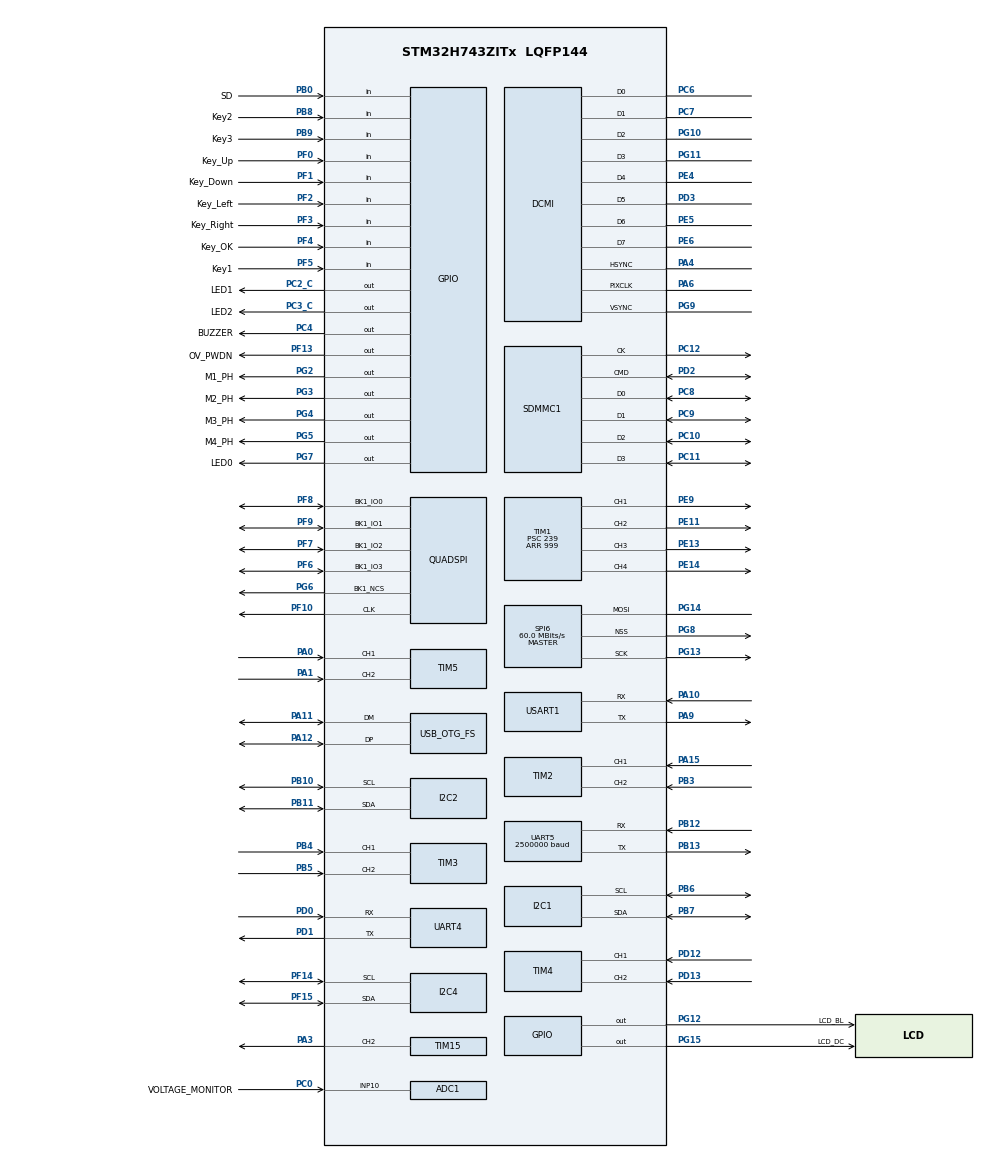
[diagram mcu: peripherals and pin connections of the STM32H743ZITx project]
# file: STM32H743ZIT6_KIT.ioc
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ADC1.Channel-2\#ChannelRegularConversion=ADC_CHANNEL_10
ADC1.NbrOfConversionFlag=1
ADC1.OffsetNumber-2\#ChannelRegularConversion=ADC_OFFSET_NONE
ADC1.OffsetSignedSaturation-2\#ChannelRegularConversion=DISABLE
ADC1.Rank-2\#ChannelRegularConversion=1
ADC1.SamplingTime-2\#ChannelRegularConversion=ADC_SAMPLETIME_387CYCLES_5
ADC1.master=1
Bdma.Request0=SPI6_TX
Bdma.RequestsNb=1
Bdma.SPI6_TX.0.Direction=DMA_MEMORY_TO_PERIPH
Bdma.SPI6_TX.0.EventEnable=DISABLE
Bdma.SPI6_TX.0.Instance=BDMA_Channel0
Bdma.SPI6_TX.0.MemDataAlignment=DMA_MDATAALIGN_HALFWORD
Bdma.SPI6_TX.0.MemInc=DMA_MINC_ENABLE
Bdma.SPI6_TX.0.Mode=DMA_NORMAL
Bdma.SPI6_TX.0.PeriphDataAlignment=DMA_PDATAALIGN_HALFWORD
Bdma.SPI6_TX.0.PeriphInc=DMA_PINC_DISABLE
Bdma.SPI6_TX.0.Polarity=HAL_DMAMUX_REQ_GEN_RISING
Bdma.SPI6_TX.0.Priority=DMA_PRIORITY_HIGH
Bdma.SPI6_TX.0.RequestNumber=1
Bdma.SPI6_TX.0.SignalID=NONE
Bdma.SPI6_TX.0.SyncEnable=DISABLE
Bdma.SPI6_TX.0.SyncPolarity=HAL_DMAMUX_SYNC_NO_EVENT
Bdma.SPI6_TX.0.SyncRequestNumber=1
Bdma.SPI6_TX.0.SyncSignalID=NONE
CORTEX_M7.default_mode_Activation=1
DAC1.DAC_Channel-DAC_OUT1_Int=DAC_CHANNEL_1
DCMI.JPEGMode=DCMI_JPEG_ENABLE
DCMI.PCKPolarity=DCMI_PCKPOLARITY_RISING
DCMI.VSPolarity=DCMI_VSPOLARITY_HIGH
DMA2D.ChromaSubSamplingForeground=DMA2D_CSS_420
DMA2D.ColorMode=DMA2D_OUTPUT_RGB565
DMA2D.InputColorModeForeground=DMA2D_INPUT_YCBCR
DMA2D.Mode=DMA2D_M2M_PFC
Dma.DCMI.1.Direction=DMA_PERIPH_TO_MEMORY
Dma.DCMI.1.EventEnable=DISABLE
Dma.DCMI.1.FIFOMode=DMA_FIFOMODE_ENABLE
Dma.DCMI.1.FIFOThreshold=DMA_FIFO_THRESHOLD_FULL
Dma.DCMI.1.Instance=DMA1_Stream1
Dma.DCMI.1.MemBurst=DMA_MBURST_SINGLE
Dma.DCMI.1.MemDataAlignment=DMA_MDATAALIGN_WORD
Dma.DCMI.1.MemInc=DMA_MINC_ENABLE
Dma.DCMI.1.Mode=DMA_NORMAL
Dma.DCMI.1.PeriphBurst=DMA_PBURST_SINGLE
Dma.DCMI.1.PeriphDataAlignment=DMA_PDATAALIGN_WORD
Dma.DCMI.1.PeriphInc=DMA_PINC_DISABLE
Dma.DCMI.1.Polarity=HAL_DMAMUX_REQ_GEN_RISING
Dma.DCMI.1.Priority=DMA_PRIORITY_VERY_HIGH
Dma.DCMI.1.RequestNumber=1
Dma.DCMI.1.SignalID=NONE
Dma.DCMI.1.SyncEnable=DISABLE
Dma.DCMI.1.SyncPolarity=HAL_DMAMUX_SYNC_NO_EVENT
Dma.DCMI.1.SyncRequestNumber=1
Dma.DCMI.1.SyncSignalID=NONE
Dma.Request0=TIM15_UP
Dma.Request1=DCMI
Dma.Request2=UART5_TX
Dma.TIM15_UP.0.Direction=DMA_MEMORY_TO_PERIPH
Dma.TIM15_UP.0.EventEnable=DISABLE
Dma.TIM15_UP.0.FIFOMode=DMA_FIFOMODE_DISABLE
Dma.TIM15_UP.0.Instance=DMA1_Stream0
Dma.TIM15_UP.0.MemDataAlignment=DMA_MDATAALIGN_HALFWORD
Dma.TIM15_UP.0.MemInc=DMA_MINC_ENABLE
Dma.TIM15_UP.0.Mode=DMA_NORMAL
Dma.TIM15_UP.0.PeriphDataAlignment=DMA_PDATAALIGN_HALFWORD
Dma.TIM15_UP.0.PeriphInc=DMA_PINC_DISABLE
Dma.TIM15_UP.0.Polarity=HAL_DMAMUX_REQ_GEN_RISING
Dma.TIM15_UP.0.Priority=DMA_PRIORITY_LOW
Dma.TIM15_UP.0.RequestNumber=1
Dma.TIM15_UP.0.SignalID=NONE
Dma.TIM15_UP.0.SyncEnable=DISABLE
Dma.TIM15_UP.0.SyncPolarity=HAL_DMAMUX_SYNC_NO_EVENT
Dma.TIM15_UP.0.SyncRequestNumber=1
Dma.TIM15_UP.0.SyncSignalID=NONE
Dma.UART5_TX.2.Direction=DMA_MEMORY_TO_PERIPH
Dma.UART5_TX.2.EventEnable=DISABLE
Dma.UART5_TX.2.FIFOMode=DMA_FIFOMODE_DISABLE
Dma.UART5_TX.2.Instance=DMA1_Stream2
Dma.UART5_TX.2.MemDataAlignment=DMA_MDATAALIGN_BYTE
Dma.UART5_TX.2.MemInc=DMA_MINC_ENABLE
Dma.UART5_TX.2.Mode=DMA_NORMAL
Dma.UART5_TX.2.PeriphDataAlignment=DMA_PDATAALIGN_BYTE
Dma.UART5_TX.2.PeriphInc=DMA_PINC_DISABLE
Dma.UART5_TX.2.Polarity=HAL_DMAMUX_REQ_GEN_RISING
Dma.UART5_TX.2.Priority=DMA_PRIORITY_HIGH
Dma.UART5_TX.2.RequestNumber=1
Dma.UART5_TX.2.SignalID=NONE
Dma.UART5_TX.2.SyncEnable=DISABLE
Dma.UART5_TX.2.SyncPolarity=HAL_DMAMUX_SYNC_NO_EVENT
Dma.UART5_TX.2.SyncRequestNumber=1
Dma.UART5_TX.2.SyncSignalID=NONE
FATFS.BSP.number=1
FATFS.USE_DMA_CODE_SD=1
FATFS._CODE_PAGE=936
FATFS._USE_LFN=2
FATFS0.BSP.STBoard=false
FATFS0.BSP.api=Unknown
FATFS0.BSP.instance=PB0
FATFS0.BSP.ip=GPIO
FATFS0.BSP.mode=Input
FATFS0.BSP.name=Detect_SDIO
FATFS0.BSP.solution=PB0
I2C1.Timing=0x307075B1
I2C2.Timing=0x307075B1
I2C4.Timing=0x707075B1
IWDG1.Prescaler=IWDG_PRESCALER_64
IWDG1.Reload=3999
IWDG1.Window=4095
Mcu.Family=STM32H7
Mcu.Name=STM32H743ZITx
Mcu.Package=LQFP144
Mdma.MDMA_Channel0.JPEG_INFIFO_TH.0.BlockCount=0
Mdma.MDMA_Channel0.JPEG_INFIFO_TH.0.BlockDataLength=0
Mdma.MDMA_Channel0.JPEG_INFIFO_TH.0.BufferTransferLength=32
Mdma.MDMA_Channel0.JPEG_INFIFO_TH.0.CircularMode=MDMA_LINEAR_LIST
Mdma.MDMA_Channel0.JPEG_INFIFO_TH.0.DataAlignment=MDMA_DATAALIGN_PACKENABLE
Mdma.MDMA_Channel0.JPEG_INFIFO_TH.0.DestBlockAddressOffset=0
Mdma.MDMA_Channel0.JPEG_INFIFO_TH.0.DestBurst=MDMA_DEST_BURST_SINGLE
Mdma.MDMA_Channel0.JPEG_INFIFO_TH.0.DestDataSize=MDMA_DEST_DATASIZE_WORD
Mdma.MDMA_Channel0.JPEG_INFIFO_TH.0.DestinationInc=MDMA_DEST_INC_DISABLE
Mdma.MDMA_Channel0.JPEG_INFIFO_TH.0.DstAddress=0
Mdma.MDMA_Channel0.JPEG_INFIFO_TH.0.Endianness=MDMA_LITTLE_ENDIANNESS_PRESERVE
Mdma.MDMA_Channel0.JPEG_INFIFO_TH.0.Instance=MDMA_Channel0
Mdma.MDMA_Channel0.JPEG_INFIFO_TH.0.MaskAddress=0
Mdma.MDMA_Channel0.JPEG_INFIFO_TH.0.MaskData=0
Mdma.MDMA_Channel0.JPEG_INFIFO_TH.0.Priority=MDMA_PRIORITY_VERY_HIGH
Mdma.MDMA_Channel0.JPEG_INFIFO_TH.0.Rank=First
Mdma.MDMA_Channel0.JPEG_INFIFO_TH.0.SourceBlockAddressOffset=0
Mdma.MDMA_Channel0.JPEG_INFIFO_TH.0.SourceBurst=MDMA_SOURCE_BURST_SINGLE
Mdma.MDMA_Channel0.JPEG_INFIFO_TH.0.SourceDataSize=MDMA_SRC_DATASIZE_BYTE
Mdma.MDMA_Channel0.JPEG_INFIFO_TH.0.SourceInc=MDMA_SRC_INC_BYTE
Mdma.MDMA_Channel0.JPEG_INFIFO_TH.0.SrcAddress=0
Mdma.MDMA_Channel0.JPEG_INFIFO_TH.0.TransferTriggerMode=MDMA_BUFFER_TRANSFER
Mdma.MDMA_Channel0.Request0=JPEG_INFIFO_TH
Mdma.MDMA_Channel0.RequestsNb=1
Mdma.MDMA_Channel1.JPEG_OUTFIFO_TH.0.BlockCount=0
Mdma.MDMA_Channel1.JPEG_OUTFIFO_TH.0.BlockDataLength=0
Mdma.MDMA_Channel1.JPEG_OUTFIFO_TH.0.BufferTransferLength=32
Mdma.MDMA_Channel1.JPEG_OUTFIFO_TH.0.CircularMode=MDMA_LINEAR_LIST
Mdma.MDMA_Channel1.JPEG_OUTFIFO_TH.0.DataAlignment=MDMA_DATAALIGN_PACKENABLE
Mdma.MDMA_Channel1.JPEG_OUTFIFO_TH.0.DestBlockAddressOffset=0
Mdma.MDMA_Channel1.JPEG_OUTFIFO_TH.0.DestBurst=MDMA_DEST_BURST_SINGLE
Mdma.MDMA_Channel1.JPEG_OUTFIFO_TH.0.DestDataSize=MDMA_DEST_DATASIZE_BYTE
Mdma.MDMA_Channel1.JPEG_OUTFIFO_TH.0.DestinationInc=MDMA_DEST_INC_BYTE
Mdma.MDMA_Channel1.JPEG_OUTFIFO_TH.0.DstAddress=0
Mdma.MDMA_Channel1.JPEG_OUTFIFO_TH.0.Endianness=MDMA_LITTLE_ENDIANNESS_PRESERVE
Mdma.MDMA_Channel1.JPEG_OUTFIFO_TH.0.Instance=MDMA_Channel1
Mdma.MDMA_Channel1.JPEG_OUTFIFO_TH.0.MaskAddress=0
Mdma.MDMA_Channel1.JPEG_OUTFIFO_TH.0.MaskData=0
Mdma.MDMA_Channel1.JPEG_OUTFIFO_TH.0.Priority=MDMA_PRIORITY_VERY_HIGH
Mdma.MDMA_Channel1.JPEG_OUTFIFO_TH.0.Rank=First
Mdma.MDMA_Channel1.JPEG_OUTFIFO_TH.0.SourceBlockAddressOffset=0
Mdma.MDMA_Channel1.JPEG_OUTFIFO_TH.0.SourceBurst=MDMA_SOURCE_BURST_SINGLE
Mdma.MDMA_Channel1.JPEG_OUTFIFO_TH.0.SourceDataSize=MDMA_SRC_DATASIZE_WORD
Mdma.MDMA_Channel1.JPEG_OUTFIFO_TH.0.SourceInc=MDMA_SRC_INC_DISABLE
Mdma.MDMA_Channel1.JPEG_OUTFIFO_TH.0.SrcAddress=0
Mdma.MDMA_Channel1.JPEG_OUTFIFO_TH.0.TransferTriggerMode=MDMA_BUFFER_TRANSFER
Mdma.MDMA_Channel1.Request0=JPEG_OUTFIFO_TH
Mdma.MDMA_Channel1.RequestsNb=1
Mdma.RequestSet0=MDMA_Channel0
Mdma.RequestSet1=MDMA_Channel1
Mdma.RequestSetsNb=2
NVIC.ADC_IRQn=true\:12\:0\:true\:false\:true\:true\:true\:true
NVIC.BDMA_Channel0_IRQn=true\:7\:0\:true\:false\:true\:false\:true\:true
NVIC.DCMI_IRQn=true\:6\:0\:true\:false\:true\:true\:true\:true
NVIC.DMA1_Stream0_IRQn=true\:7\:0\:true\:false\:true\:false\:true\:true
NVIC.DMA1_Stream1_IRQn=true\:6\:0\:true\:false\:true\:false\:true\:true
NVIC.DMA1_Stream2_IRQn=true\:7\:0\:true\:false\:true\:false\:true\:true
NVIC.DMA2D_IRQn=true\:9\:0\:true\:false\:true\:true\:true\:true
NVIC.JPEG_IRQn=true\:9\:0\:true\:false\:true\:true\:true\:true
NVIC.MDMA_IRQn=true\:9\:0\:true\:false\:true\:false\:true\:true
NVIC.OTG_FS_IRQn=true\:6\:0\:true\:false\:true\:true\:true\:true
NVIC.PriorityGroup=NVIC_PRIORITYGROUP_4
NVIC.SDMMC1_IRQn=true\:10\:0\:true\:false\:true\:true\:true\:true
NVIC.SPI6_IRQn=true\:7\:0\:true\:false\:true\:false\:true\:true
NVIC.TIM16_IRQn=true\:15\:0\:true\:false\:true\:true\:true\:true
NVIC.TIM6_DAC_IRQn=true\:3\:0\:true\:false\:true\:true\:true\:true
NVIC.TIM7_IRQn=true\:4\:0\:true\:false\:true\:true\:true\:true
NVIC.TIM8_UP_TIM13_IRQn=true\:1\:0\:true\:false\:true\:true\:true\:true
NVIC.UART4_IRQn=true\:6\:0\:true\:false\:true\:true\:true\:true
NVIC.UART5_IRQn=true\:5\:0\:true\:false\:true\:true\:true\:true
PA0.Signal=S_TIM5_CH1
PA1.Signal=S_TIM5_CH2
PA10.Mode=Asynchronous
PA10.Signal=USART1_RX
PA11.Mode=Device_Only
PA11.Signal=USB_OTG_FS_DM
PA12.Mode=Device_Only
PA12.Signal=USB_OTG_FS_DP
PA13\ (JTMS/SWDIO).Mode=Serial_Wire
PA13\ (JTMS/SWDIO).Signal=DEBUG_JTMS-SWDIO
PA14\ (JTCK/SWCLK).Mode=Serial_Wire
PA14\ (JTCK/SWCLK).Signal=DEBUG_JTCK-SWCLK
PA15\ (JTDI).Signal=S_TIM2_CH1_ETR
PA3.Signal=S_TIM15_CH2
PA4.GPIO_Speed=GPIO_SPEED_FREQ_VERY_HIGH
PA4.Mode=Slave_8_bits_External_Synchro
PA4.Signal=DCMI_HSYNC
PA6.GPIO_Speed=GPIO_SPEED_FREQ_VERY_HIGH
PA6.Mode=Slave_8_bits_External_Synchro
PA6.Signal=DCMI_PIXCLK
PA9.Mode=Asynchronous
PA9.Signal=USART1_TX
PB0.GPIO_Label=SD
PB0.GPIO_PuPd=GPIO_PULLUP
PB0.Signal=GPIO_Input
PB10.Mode=I2C
PB10.Signal=I2C2_SCL
PB11.Mode=I2C
PB11.Signal=I2C2_SDA
PB12.Mode=Asynchronous
PB12.Signal=UART5_RX
PB13.GPIO_Speed=GPIO_SPEED_FREQ_VERY_HIGH
PB13.Mode=Asynchronous
PB13.Signal=UART5_TX
PB3\ (JTDO/TRACESWO).Signal=S_TIM2_CH2
PB4\ (NJTRST).Signal=S_TIM3_CH1
PB5.Signal=S_TIM3_CH2
PB6.Mode=I2C
PB6.Signal=I2C1_SCL
PB7.Mode=I2C
PB7.Signal=I2C1_SDA
PB8.GPIO_Label=Key2
PB8.GPIO_PuPd=GPIO_PULLUP
PB8.Signal=GPIO_Input
PB9.GPIO_Label=Key3
PB9.GPIO_PuPd=GPIO_PULLUP
PB9.Signal=GPIO_Input
PC0.GPIO_Label=VOLTAGE_MONITOR
PC0.Signal=ADCx_INP10
PC10.GPIO_PuPd=GPIO_PULLUP
PC10.Mode=SD_4_bits_Wide_bus
PC10.Signal=SDMMC1_D2
PC11.GPIO_PuPd=GPIO_PULLUP
PC11.Mode=SD_4_bits_Wide_bus
PC11.Signal=SDMMC1_D3
PC12.Mode=SD_4_bits_Wide_bus
PC12.Signal=SDMMC1_CK
PC14-OSC32_IN\ (OSC32_IN).Mode=LSE-External-Oscillator
PC14-OSC32_IN\ (OSC32_IN).Signal=RCC_OSC32_IN
PC15-OSC32_OUT\ (OSC32_OUT).Mode=LSE-External-Oscillator
PC15-OSC32_OUT\ (OSC32_OUT).Signal=RCC_OSC32_OUT
PC2_C.GPIO_Label=LED1
PC2_C.GPIO_PuPd=GPIO_PULLUP
PC2_C.PinState=GPIO_PIN_SET
PC2_C.Signal=GPIO_Output
PC3_C.GPIO_Label=LED2
PC3_C.GPIO_PuPd=GPIO_PULLUP
PC3_C.PinState=GPIO_PIN_SET
PC3_C.Signal=GPIO_Output
PC4.GPIO_Label=BUZZER
PC4.GPIO_ModeDefaultOutputPP=GPIO_MODE_OUTPUT_PP
PC4.GPIO_PuPd=GPIO_NOPULL
PC4.Signal=GPIO_Output
PC6.GPIO_Speed=GPIO_SPEED_FREQ_VERY_HIGH
PC6.Mode=Slave_8_bits_External_Synchro
PC6.Signal=DCMI_D0
PC7.GPIO_Speed=GPIO_SPEED_FREQ_VERY_HIGH
PC7.Mode=Slave_8_bits_External_Synchro
PC7.Signal=DCMI_D1
PC8.GPIO_PuPd=GPIO_PULLUP
PC8.Mode=SD_4_bits_Wide_bus
PC8.Signal=SDMMC1_D0
PC9.GPIO_PuPd=GPIO_PULLUP
PC9.Mode=SD_4_bits_Wide_bus
PC9.Signal=SDMMC1_D1
PD0.Mode=Asynchronous
PD0.Signal=UART4_RX
PD1.Mode=Asynchronous
PD1.Signal=UART4_TX
PD12.Signal=S_TIM4_CH1
PD13.Signal=S_TIM4_CH2
PD2.GPIO_PuPd=GPIO_PULLUP
PD2.Mode=SD_4_bits_Wide_bus
PD2.Signal=SDMMC1_CMD
PD3.GPIO_Speed=GPIO_SPEED_FREQ_VERY_HIGH
PD3.Mode=Slave_8_bits_External_Synchro
PD3.Signal=DCMI_D5
PE11.Signal=S_TIM1_CH2
PE13.Signal=S_TIM1_CH3
PE14.Signal=S_TIM1_CH4
PE4.GPIO_Speed=GPIO_SPEED_FREQ_VERY_HIGH
PE4.Mode=Slave_8_bits_External_Synchro
PE4.Signal=DCMI_D4
PE5.GPIO_Speed=GPIO_SPEED_FREQ_VERY_HIGH
PE5.Mode=Slave_8_bits_External_Synchro
PE5.Signal=DCMI_D6
PE6.GPIO_Speed=GPIO_SPEED_FREQ_VERY_HIGH
PE6.Mode=Slave_8_bits_External_Synchro
PE6.Signal=DCMI_D7
PE9.Signal=S_TIM1_CH1
PF0.GPIO_Label=Key_Up
PF0.GPIO_PuPd=GPIO_PULLUP
PF0.Signal=GPIO_Input
PF1.GPIO_Label=Key_Down
PF1.GPIO_PuPd=GPIO_PULLUP
PF1.Signal=GPIO_Input
PF10.Mode=Single Bank 1
PF10.Signal=QUADSPI_CLK
PF13.GPIO_Label=OV_PWDN
PF13.PinState=GPIO_PIN_SET
PF13.Signal=GPIO_Output
PF14.GPIO_PuPd=GPIO_NOPULL
PF14.Mode=I2C
PF14.Signal=I2C4_SCL
PF15.GPIO_PuPd=GPIO_NOPULL
PF15.Mode=I2C
PF15.Signal=I2C4_SDA
PF2.GPIO_Label=Key_Left
PF2.GPIO_PuPd=GPIO_PULLUP
PF2.Signal=GPIO_Input
PF3.GPIO_Label=Key_Right
PF3.GPIO_PuPd=GPIO_PULLUP
PF3.Signal=GPIO_Input
PF4.GPIO_Label=Key_OK
PF4.GPIO_PuPd=GPIO_PULLUP
PF4.Signal=GPIO_Input
PF5.GPIO_Label=Key1
PF5.GPIO_PuPd=GPIO_PULLUP
PF5.Signal=GPIO_Input
PF6.Mode=Single Bank 1
PF6.Signal=QUADSPI_BK1_IO3
PF7.Mode=Single Bank 1
PF7.Signal=QUADSPI_BK1_IO2
PF8.Mode=Single Bank 1
PF8.Signal=QUADSPI_BK1_IO0
PF9.Mode=Single Bank 1
PF9.Signal=QUADSPI_BK1_IO1
PG10.GPIO_Speed=GPIO_SPEED_FREQ_VERY_HIGH
PG10.Mode=Slave_8_bits_External_Synchro
PG10.Signal=DCMI_D2
PG11.GPIO_Speed=GPIO_SPEED_FREQ_VERY_HIGH
PG11.Mode=Slave_8_bits_External_Synchro
PG11.Signal=DCMI_D3
PG12.GPIO_Label=LCD_BL
PG12.Signal=GPIO_Output
PG13.Mode=Simplex_Bidirectional_Master
PG13.Signal=SPI6_SCK
PG14.Mode=Simplex_Bidirectional_Master
PG14.Signal=SPI6_MOSI
PG15.GPIO_Label=LCD_DC
PG15.Signal=GPIO_Output
PG2.GPIO_Label=M1_PH
PG2.GPIO_PuPd=GPIO_PULLDOWN
PG2.GPIO_Speed=GPIO_SPEED_FREQ_HIGH
PG2.Signal=GPIO_Output
PG3.GPIO_Label=M2_PH
PG3.GPIO_PuPd=GPIO_PULLDOWN
PG3.GPIO_Speed=GPIO_SPEED_FREQ_HIGH
PG3.Signal=GPIO_Output
PG4.GPIO_Label=M3_PH
PG4.GPIO_PuPd=GPIO_PULLDOWN
PG4.GPIO_Speed=GPIO_SPEED_FREQ_HIGH
PG4.Signal=GPIO_Output
PG5.GPIO_Label=M4_PH
PG5.GPIO_PuPd=GPIO_PULLDOWN
PG5.GPIO_Speed=GPIO_SPEED_FREQ_HIGH
PG5.Signal=GPIO_Output
PG6.Mode=Single Bank 1
PG6.Signal=QUADSPI_BK1_NCS
PG7.GPIO_Label=LED0
PG7.GPIO_PuPd=GPIO_PULLUP
PG7.PinState=GPIO_PIN_SET
PG7.Signal=GPIO_Output
PG8.Mode=NSS_Signal_Hard_Output
PG8.Signal=SPI6_NSS
PG9.GPIO_Speed=GPIO_SPEED_FREQ_VERY_HIGH
PG9.Mode=Slave_8_bits_External_Synchro
PG9.Signal=DCMI_VSYNC
PH0-OSC_IN\ (PH0).Mode=HSE-External-Oscillator
PH0-OSC_IN\ (PH0).Signal=RCC_OSC_IN
PH1-OSC_OUT\ (PH1).Mode=HSE-External-Oscillator
PH1-OSC_OUT\ (PH1).Signal=RCC_OSC_OUT
ProjectManager.HeapSize=0x200
ProjectManager.StackSize=0x2000
ProjectManager.TargetToolchain=CMake
QUADSPI.ClockMode=QSPI_CLOCK_MODE_3
QUADSPI.ClockPrescaler=3
QUADSPI.FifoThreshold=32
QUADSPI.FlashSize=22
QUADSPI.SampleShifting=QSPI_SAMPLE_SHIFTING_HALFCYCLE
RCC.ADCFreq_Value=75000000
RCC.APB1Freq_Value=120000000
RCC.APB2Freq_Value=120000000
RCC.APB3Freq_Value=120000000
RCC.APB4Freq_Value=120000000
RCC.CortexFreq_Value=480000000
RCC.D1PPRE=RCC_APB3_DIV2
RCC.D2PPRE1=RCC_APB1_DIV2
RCC.D2PPRE2=RCC_APB2_DIV2
RCC.D3PPRE=RCC_APB4_DIV2
RCC.DIVM1=5
RCC.DIVM2=2
RCC.DIVN1=192
RCC.DIVN2=12
RCC.DIVQ1=5
RCC.HCLKFreq_Value=240000000
RCC.HPRE=RCC_HCLK_DIV2
RCC.PLL2FRACN=0
RCC.PLL3FRACN=0
RCC.PLLFRACN=0
RCC.PLLSourceVirtual=RCC_PLLSOURCE_HSE
RCC.SYSCLKFreq_VALUE=480000000
RCC.SYSCLKSource=RCC_SYSCLKSOURCE_PLLCLK
RCC.USBCLockSelection=RCC_USBCLKSOURCE_HSI48
RCC.USBFreq_Value=48000000
SDMMC1.ClockDiv=6
SH.ADCx_INP10.0=ADC1_INP10,IN10-Single-Ended
SH.S_TIM15_CH2.0=TIM15_CH2,PWM Generation2 CH2
SH.S_TIM1_CH1.0=TIM1_CH1,PWM Generation1 CH1
SH.S_TIM1_CH2.0=TIM1_CH2,PWM Generation2 CH2
SH.S_TIM1_CH3.0=TIM1_CH3,PWM Generation3 CH3
SH.S_TIM1_CH4.0=TIM1_CH4,PWM Generation4 CH4
SH.S_TIM2_CH1_ETR.0=TIM2_CH1,Encoder_Interface
SH.S_TIM2_CH2.0=TIM2_CH2,Encoder_Interface
SH.S_TIM3_CH1.0=TIM3_CH1,Encoder_Interface
SH.S_TIM3_CH2.0=TIM3_CH2,Encoder_Interface
SH.S_TIM4_CH1.0=TIM4_CH1,Encoder_Interface
SH.S_TIM4_CH2.0=TIM4_CH2,Encoder_Interface
SH.S_TIM5_CH1.0=TIM5_CH1,Encoder_Interface
SH.S_TIM5_CH2.0=TIM5_CH2,Encoder_Interface
SPI6.CLKPolarity=SPI_POLARITY_LOW
SPI6.CalculateBaudRate=60.0 MBits/s
SPI6.DataSize=SPI_DATASIZE_8BIT
SPI6.Direction=SPI_DIRECTION_1LINE
SPI6.Mode=SPI_MODE_MASTER
SPI6.VirtualNSS=VM_NSSHARD
SPI6.VirtualType=VM_MASTER
TIM1.Channel-PWM\ Generation1\ CH1=TIM_CHANNEL_1
TIM1.Channel-PWM\ Generation2\ CH2=TIM_CHANNEL_2
TIM1.Channel-PWM\ Generation3\ CH3=TIM_CHANNEL_3
TIM1.Channel-PWM\ Generation4\ CH4=TIM_CHANNEL_4
TIM1.Period=999
TIM1.Prescaler=239
TIM13.Period=999
TIM13.Prescaler=2399
TIM15.Channel-PWM\ Generation2\ CH2=TIM_CHANNEL_2
TIM15.Period=299
TIM16.Period=10000-1
TIM16.Prescaler=24000-1
TIM6.Period=999
TIM6.Prescaler=239
TIM7.Period=332
TIM7.Prescaler=24000-1
UART5.BaudRate=2500000
USART1.VirtualMode-Asynchronous=VM_ASYNC
USB_DEVICE.CLASS_NAME_FS=CDC
USB_DEVICE.VirtualMode-CDC_FS=Cdc
USB_DEVICE.VirtualModeFS=Cdc_FS
USB_OTG_FS.VirtualMode=Device_Only
VP_DAC1_VS_DACI1.Mode=DAC_OUT1_Int
VP_DMA2D_VS_DMA2D.Mode=DMA2D_Activate
VP_FATFS_VS_SDIO.Mode=SDIO
VP_IWDG1_VS_IWDG.Mode=IWDG_Activate
VP_JPEG_VS_JPEG.Mode=JPEG_Activate
VP_MEMORYMAP_VS_MEMORYMAP.Mode=CurAppReg
VP_TIM13_VS_ClockSourceINT.Mode=Enable_Timer
VP_TIM16_VS_ClockSourceINT.Mode=Enable_Timer
VP_TIM6_VS_ClockSourceINT.Mode=Enable_Timer
VP_TIM7_VS_ClockSourceINT.Mode=Enable_Timer
VP_USB_DEVICE_VS_USB_DEVICE_CDC_FS.Mode=CDC_FS
board=custom

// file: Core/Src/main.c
/* USER CODE BEGIN Header */
/**
  ******************************************************************************
  * @file           : main.c
  * @brief          : Main program body
  ******************************************************************************
  * @attention
  *
  * Copyright (c) 2026 STMicroelectronics.
  * All rights reserved.
  *
  * This software is licensed under terms that can be found in the LICENSE file
  * in the root directory of this software component.
  * If no LICENSE file comes with this software, it is provided AS-IS.
  *
  ******************************************************************************
  */
/* USER CODE END Header */
#include "main.h"
#include "fatfs.h"
#include "usb_device.h"

/* USER CODE BEGIN Includes */
#include "app_boot.h"
#include "app_runtime.h"
#include "runtime_monitor.h"

/* USER CODE END Includes */

ADC_HandleTypeDef hadc1;

DAC_HandleTypeDef hdac1;

DCMI_HandleTypeDef hdcmi;
DMA_HandleTypeDef hdma_dcmi;

DMA2D_HandleTypeDef hdma2d;

I2C_HandleTypeDef hi2c1;
I2C_HandleTypeDef hi2c2;
I2C_HandleTypeDef hi2c4;

IWDG_HandleTypeDef hiwdg1;

JPEG_HandleTypeDef hjpeg;
MDMA_HandleTypeDef hmdma_jpeg_infifo_th;
MDMA_HandleTypeDef hmdma_jpeg_outfifo_th;

QSPI_HandleTypeDef hqspi;

SD_HandleTypeDef hsd1;

SPI_HandleTypeDef hspi6;
DMA_HandleTypeDef hdma_spi6_tx;

TIM_HandleTypeDef htim1;
TIM_HandleTypeDef htim2;
TIM_HandleTypeDef htim3;
TIM_HandleTypeDef htim4;
TIM_HandleTypeDef htim5;
TIM_HandleTypeDef htim6;
TIM_HandleTypeDef htim7;
TIM_HandleTypeDef htim13;
TIM_HandleTypeDef htim15;
TIM_HandleTypeDef htim16;
DMA_HandleTypeDef hdma_tim15_up;

UART_HandleTypeDef huart4;
UART_HandleTypeDef huart5;
UART_HandleTypeDef huart1;
DMA_HandleTypeDef hdma_uart5_tx;

void SystemClock_Config(void);
static void MPU_Config(void);
static void MX_GPIO_Init(void);
static void MX_BDMA_Init(void);
static void MX_MDMA_Init(void);
static void MX_DMA_Init(void);
static void MX_DAC1_Init(void);
static void MX_TIM1_Init(void);
static void MX_TIM2_Init(void);
static void MX_TIM3_Init(void);
static void MX_TIM4_Init(void);
static void MX_TIM5_Init(void);
static void MX_I2C4_Init(void);
static void MX_SPI6_Init(void);
static void MX_QUADSPI_Init(void);
static void MX_USART1_UART_Init(void);
static void MX_TIM15_Init(void);
static void MX_UART4_Init(void);
static void MX_I2C1_Init(void);
static void MX_I2C2_Init(void);
static void MX_UART5_Init(void);
static void MX_ADC1_Init(void);
static void MX_SDMMC1_SD_Init(void);
static void MX_JPEG_Init(void);
static void MX_TIM6_Init(void);
static void MX_DMA2D_Init(void);
static void MX_TIM7_Init(void);
static void MX_TIM13_Init(void);
static void MX_TIM16_Init(void);
static void MX_DCMI_Init(void);
static void MX_IWDG1_Init(void);

int main(void)
{

  /* MPU Configuration--------------------------------------------------------*/
  MPU_Config();

  /* MCU Configuration--------------------------------------------------------*/

  /* Reset of all peripherals, Initializes the Flash interface and the Systick. */
  HAL_Init();

  /* USER CODE BEGIN Init */
  AppBoot_EnableCache();

  /* USER CODE END Init */

  /* Configure the system clock */
  SystemClock_Config();

  /* USER CODE BEGIN SysInit */
  AppRuntime_EarlyInit();

  /* USER CODE END SysInit */

  /* Initialize all configured peripherals */
  MX_GPIO_Init();
  MX_BDMA_Init();
  MX_MDMA_Init();
  MX_DMA_Init();
  MX_DAC1_Init();
  MX_TIM1_Init();
  MX_TIM2_Init();
  MX_TIM3_Init();
  MX_TIM4_Init();
  MX_TIM5_Init();
  MX_I2C4_Init();
  MX_SPI6_Init();
  MX_QUADSPI_Init();
  MX_USART1_UART_Init();
  MX_TIM15_Init();
  MX_UART4_Init();
  MX_I2C1_Init();
  MX_I2C2_Init();
  MX_UART5_Init();
  MX_ADC1_Init();
  MX_USB_DEVICE_Init();
  MX_FATFS_Init();
  MX_SDMMC1_SD_Init();
  MX_JPEG_Init();
  MX_TIM6_Init();
  MX_DMA2D_Init();
  MX_TIM7_Init();
  MX_TIM13_Init();
  MX_TIM16_Init();
  MX_DCMI_Init();
  MX_IWDG1_Init();
  /* USER CODE BEGIN 2 */
  const AppContext app_context =
  {
    .adc1 = &hadc1,
    .iwdg1 = &hiwdg1,
    .sd1 = &hsd1,
    .tim6 = &htim6,
    .tim7 = &htim7,
    .tim13 = &htim13,
    .tim16 = &htim16,
    .uart4 = &huart4,
    .uart5 = &huart5,
    .jpeg_init_ok = 0U,
    .dma2d_init_ok = 0U,
    .tim7_init_ok = 0U
  };

  AppRuntime_Init(&app_context);
  /* USER CODE END 2 */

  /* Infinite loop */
  while (1)
  {

    /* USER CODE BEGIN 3 */
    AppRuntime_Process();
    HAL_Delay(AppRuntime_GetIdleDelayMs());
  }
  /* USER CODE END 3 */
}

void SystemClock_Config(void)
{
  RCC_OscInitTypeDef RCC_OscInitStruct = {0};
  RCC_ClkInitTypeDef RCC_ClkInitStruct = {0};

  /** Supply configuration update enable
  */
  HAL_PWREx_ConfigSupply(PWR_LDO_SUPPLY);

  /** Configure the main internal regulator output voltage
  */
  __HAL_PWR_VOLTAGESCALING_CONFIG(PWR_REGULATOR_VOLTAGE_SCALE0);

  while(!__HAL_PWR_GET_FLAG(PWR_FLAG_VOSRDY)) {}

  /** Initializes the RCC Oscillators according to the specified parameters
  * in the RCC_OscInitTypeDef structure.
  */
  RCC_OscInitStruct.OscillatorType = RCC_OSCILLATORTYPE_HSI48|RCC_OSCILLATORTYPE_LSI
                              |RCC_OSCILLATORTYPE_HSE;
  RCC_OscInitStruct.HSEState = RCC_HSE_ON;
  RCC_OscInitStruct.LSIState = RCC_LSI_ON;
  RCC_OscInitStruct.HSI48State = RCC_HSI48_ON;
  RCC_OscInitStruct.PLL.PLLState = RCC_PLL_ON;
  RCC_OscInitStruct.PLL.PLLSource = RCC_PLLSOURCE_HSE;
  RCC_OscInitStruct.PLL.PLLM = 5;
  RCC_OscInitStruct.PLL.PLLN = 192;
  RCC_OscInitStruct.PLL.PLLP = 2;
  RCC_OscInitStruct.PLL.PLLQ = 5;
  RCC_OscInitStruct.PLL.PLLR = 2;
  RCC_OscInitStruct.PLL.PLLRGE = RCC_PLL1VCIRANGE_2;
  RCC_OscInitStruct.PLL.PLLVCOSEL = RCC_PLL1VCOWIDE;
  RCC_OscInitStruct.PLL.PLLFRACN = 0;
  if (HAL_RCC_OscConfig(&RCC_OscInitStruct) != HAL_OK)
  {
    Error_Handler();
  }

  /** Initializes the CPU, AHB and APB buses clocks
  */
  RCC_ClkInitStruct.ClockType = RCC_CLOCKTYPE_HCLK|RCC_CLOCKTYPE_SYSCLK
                              |RCC_CLOCKTYPE_PCLK1|RCC_CLOCKTYPE_PCLK2
                              |RCC_CLOCKTYPE_D3PCLK1|RCC_CLOCKTYPE_D1PCLK1;
  RCC_ClkInitStruct.SYSCLKSource = RCC_SYSCLKSOURCE_PLLCLK;
  RCC_ClkInitStruct.SYSCLKDivider = RCC_SYSCLK_DIV1;
  RCC_ClkInitStruct.AHBCLKDivider = RCC_HCLK_DIV2;
  RCC_ClkInitStruct.APB3CLKDivider = RCC_APB3_DIV2;
  RCC_ClkInitStruct.APB1CLKDivider = RCC_APB1_DIV2;
  RCC_ClkInitStruct.APB2CLKDivider = RCC_APB2_DIV2;
  RCC_ClkInitStruct.APB4CLKDivider = RCC_APB4_DIV2;

  if (HAL_RCC_ClockConfig(&RCC_ClkInitStruct, FLASH_LATENCY_4) != HAL_OK)
  {
    Error_Handler();
  }
}

static void MX_ADC1_Init(void)
{

  ADC_MultiModeTypeDef multimode = {0};
  ADC_ChannelConfTypeDef sConfig = {0};

  /** Common config
  */
  hadc1.Instance = ADC1;
  hadc1.Init.ClockPrescaler = ADC_CLOCK_ASYNC_DIV1;
  hadc1.Init.Resolution = ADC_RESOLUTION_16B;
  hadc1.Init.ScanConvMode = ADC_SCAN_DISABLE;
  hadc1.Init.EOCSelection = ADC_EOC_SINGLE_CONV;
  hadc1.Init.LowPowerAutoWait = DISABLE;
  hadc1.Init.ContinuousConvMode = DISABLE;
  hadc1.Init.NbrOfConversion = 1;
  hadc1.Init.DiscontinuousConvMode = DISABLE;
  hadc1.Init.ExternalTrigConv = ADC_SOFTWARE_START;
  hadc1.Init.ExternalTrigConvEdge = ADC_EXTERNALTRIGCONVEDGE_NONE;
  hadc1.Init.ConversionDataManagement = ADC_CONVERSIONDATA_DR;
  hadc1.Init.Overrun = ADC_OVR_DATA_PRESERVED;
  hadc1.Init.LeftBitShift = ADC_LEFTBITSHIFT_NONE;
  hadc1.Init.OversamplingMode = DISABLE;
  hadc1.Init.Oversampling.Ratio = 1;
  if (HAL_ADC_Init(&hadc1) != HAL_OK)
  {
    Error_Handler();
  }

  /** Configure the ADC multi-mode
  */
  multimode.Mode = ADC_MODE_INDEPENDENT;
  if (HAL_ADCEx_MultiModeConfigChannel(&hadc1, &multimode) != HAL_OK)
  {
    Error_Handler();
  }

  /** Configure Regular Channel
  */
  sConfig.Channel = ADC_CHANNEL_10;
  sConfig.Rank = ADC_REGULAR_RANK_1;
  sConfig.SamplingTime = ADC_SAMPLETIME_387CYCLES_5;
  sConfig.SingleDiff = ADC_SINGLE_ENDED;
  sConfig.OffsetNumber = ADC_OFFSET_NONE;
  sConfig.Offset = 0;
  sConfig.OffsetSignedSaturation = DISABLE;
  if (HAL_ADC_ConfigChannel(&hadc1, &sConfig) != HAL_OK)
  {
    Error_Handler();
  }

}

static void MX_DAC1_Init(void)
{

  DAC_ChannelConfTypeDef sConfig = {0};

  /** DAC Initialization
  */
  hdac1.Instance = DAC1;
  if (HAL_DAC_Init(&hdac1) != HAL_OK)
  {
    Error_Handler();
  }

  /** DAC channel OUT1 config
  */
  sConfig.DAC_SampleAndHold = DAC_SAMPLEANDHOLD_DISABLE;
  sConfig.DAC_Trigger = DAC_TRIGGER_NONE;
  sConfig.DAC_OutputBuffer = DAC_OUTPUTBUFFER_DISABLE;
  sConfig.DAC_ConnectOnChipPeripheral = DAC_CHIPCONNECT_ENABLE;
  sConfig.DAC_UserTrimming = DAC_TRIMMING_FACTORY;
  if (HAL_DAC_ConfigChannel(&hdac1, &sConfig, DAC_CHANNEL_1) != HAL_OK)
  {
    Error_Handler();
  }

}

static void MX_DCMI_Init(void)
{

  hdcmi.Instance = DCMI;
  hdcmi.Init.SynchroMode = DCMI_SYNCHRO_HARDWARE;
  hdcmi.Init.PCKPolarity = DCMI_PCKPOLARITY_RISING;
  hdcmi.Init.VSPolarity = DCMI_VSPOLARITY_HIGH;
  hdcmi.Init.HSPolarity = DCMI_HSPOLARITY_LOW;
  hdcmi.Init.CaptureRate = DCMI_CR_ALL_FRAME;
  hdcmi.Init.ExtendedDataMode = DCMI_EXTEND_DATA_8B;
  hdcmi.Init.JPEGMode = DCMI_JPEG_ENABLE;
  hdcmi.Init.ByteSelectMode = DCMI_BSM_ALL;
  hdcmi.Init.ByteSelectStart = DCMI_OEBS_ODD;
  hdcmi.Init.LineSelectMode = DCMI_LSM_ALL;
  hdcmi.Init.LineSelectStart = DCMI_OELS_ODD;
  if (HAL_DCMI_Init(&hdcmi) != HAL_OK)
  {
    Error_Handler();
  }

}

static void MX_DMA2D_Init(void)
{

  hdma2d.Instance = DMA2D;
  hdma2d.Init.Mode = DMA2D_M2M_PFC;
  hdma2d.Init.ColorMode = DMA2D_OUTPUT_RGB565;
  hdma2d.Init.OutputOffset = 0;
  hdma2d.LayerCfg[1].InputOffset = 0;
  hdma2d.LayerCfg[1].InputColorMode = DMA2D_INPUT_YCBCR;
  hdma2d.LayerCfg[1].AlphaMode = DMA2D_NO_MODIF_ALPHA;
  hdma2d.LayerCfg[1].InputAlpha = 0;
  hdma2d.LayerCfg[1].AlphaInverted = DMA2D_REGULAR_ALPHA;
  hdma2d.LayerCfg[1].RedBlueSwap = DMA2D_RB_REGULAR;
  hdma2d.LayerCfg[1].ChromaSubSampling = DMA2D_CSS_420;
  if (HAL_DMA2D_Init(&hdma2d) != HAL_OK)
  {
    Error_Handler();
  }
  if (HAL_DMA2D_ConfigLayer(&hdma2d, 1) != HAL_OK)
  {
    Error_Handler();
  }

}

static void MX_I2C1_Init(void)
{

  hi2c1.Instance = I2C1;
  hi2c1.Init.Timing = 0x307075B1;
  hi2c1.Init.OwnAddress1 = 0;
  hi2c1.Init.AddressingMode = I2C_ADDRESSINGMODE_7BIT;
  hi2c1.Init.DualAddressMode = I2C_DUALADDRESS_DISABLE;
  hi2c1.Init.OwnAddress2 = 0;
  hi2c1.Init.OwnAddress2Masks = I2C_OA2_NOMASK;
  hi2c1.Init.GeneralCallMode = I2C_GENERALCALL_DISABLE;
  hi2c1.Init.NoStretchMode = I2C_NOSTRETCH_DISABLE;
  if (HAL_I2C_Init(&hi2c1) != HAL_OK)
  {
    Error_Handler();
  }

  /** Configure Analogue filter
  */
  if (HAL_I2CEx_ConfigAnalogFilter(&hi2c1, I2C_ANALOGFILTER_ENABLE) != HAL_OK)
  {
    Error_Handler();
  }

  /** Configure Digital filter
  */
  if (HAL_I2CEx_ConfigDigitalFilter(&hi2c1, 0) != HAL_OK)
  {
    Error_Handler();
  }

}

static void MX_I2C2_Init(void)
{

  hi2c2.Instance = I2C2;
  hi2c2.Init.Timing = 0x307075B1;
  hi2c2.Init.OwnAddress1 = 0;
  hi2c2.Init.AddressingMode = I2C_ADDRESSINGMODE_7BIT;
  hi2c2.Init.DualAddressMode = I2C_DUALADDRESS_DISABLE;
  hi2c2.Init.OwnAddress2 = 0;
  hi2c2.Init.OwnAddress2Masks = I2C_OA2_NOMASK;
  hi2c2.Init.GeneralCallMode = I2C_GENERALCALL_DISABLE;
  hi2c2.Init.NoStretchMode = I2C_NOSTRETCH_DISABLE;
  if (HAL_I2C_Init(&hi2c2) != HAL_OK)
  {
    Error_Handler();
  }

  /** Configure Analogue filter
  */
  if (HAL_I2CEx_ConfigAnalogFilter(&hi2c2, I2C_ANALOGFILTER_ENABLE) != HAL_OK)
  {
    Error_Handler();
  }

  /** Configure Digital filter
  */
  if (HAL_I2CEx_ConfigDigitalFilter(&hi2c2, 0) != HAL_OK)
  {
    Error_Handler();
  }

}

static void MX_I2C4_Init(void)
{

  hi2c4.Instance = I2C4;
  hi2c4.Init.Timing = 0x707075B1;
  hi2c4.Init.OwnAddress1 = 0;
  hi2c4.Init.AddressingMode = I2C_ADDRESSINGMODE_7BIT;
  hi2c4.Init.DualAddressMode = I2C_DUALADDRESS_DISABLE;
  hi2c4.Init.OwnAddress2 = 0;
  hi2c4.Init.OwnAddress2Masks = I2C_OA2_NOMASK;
  hi2c4.Init.GeneralCallMode = I2C_GENERALCALL_DISABLE;
  hi2c4.Init.NoStretchMode = I2C_NOSTRETCH_DISABLE;
  if (HAL_I2C_Init(&hi2c4) != HAL_OK)
  {
    Error_Handler();
  }

  /** Configure Analogue filter
  */
  if (HAL_I2CEx_ConfigAnalogFilter(&hi2c4, I2C_ANALOGFILTER_ENABLE) != HAL_OK)
  {
    Error_Handler();
  }

  /** Configure Digital filter
  */
  if (HAL_I2CEx_ConfigDigitalFilter(&hi2c4, 0) != HAL_OK)
  {
    Error_Handler();
  }

}

static void MX_IWDG1_Init(void)
{

  /* USER CODE BEGIN IWDG1_Init 1 */
  /* Use the full reload range as a regular independent watchdog. CubeMX can
   * otherwise keep a near-reload window value, which rejects early feeds. */
  hiwdg1.Init.Window = 4095U;
  /* USER CODE END IWDG1_Init 1 */
  hiwdg1.Instance = IWDG1;
  hiwdg1.Init.Prescaler = IWDG_PRESCALER_64;
  hiwdg1.Init.Window = 4095;
  hiwdg1.Init.Reload = 3999;
  if (HAL_IWDG_Init(&hiwdg1) != HAL_OK)
  {
    Error_Handler();
  }
  /* USER CODE BEGIN IWDG1_Init 2 */
  /* Keep the effective window disabled even if a future .ioc regeneration
   * restores a generated near-reload value. */
  IWDG1->WINR = 4095U;
  __HAL_IWDG_RELOAD_COUNTER(&hiwdg1);
  /* USER CODE END IWDG1_Init 2 */

}

static void MX_JPEG_Init(void)
{

  hjpeg.Instance = JPEG;
  if (HAL_JPEG_Init(&hjpeg) != HAL_OK)
  {
    Error_Handler();
  }

}

static void MX_QUADSPI_Init(void)
{

  /* QUADSPI parameter configuration*/
  hqspi.Instance = QUADSPI;
  hqspi.Init.ClockPrescaler = 3;
  hqspi.Init.FifoThreshold = 32;
  hqspi.Init.SampleShifting = QSPI_SAMPLE_SHIFTING_HALFCYCLE;
  hqspi.Init.FlashSize = 22;
  hqspi.Init.ChipSelectHighTime = QSPI_CS_HIGH_TIME_1_CYCLE;
  hqspi.Init.ClockMode = QSPI_CLOCK_MODE_3;
  hqspi.Init.FlashID = QSPI_FLASH_ID_1;
  hqspi.Init.DualFlash = QSPI_DUALFLASH_DISABLE;
  if (HAL_QSPI_Init(&hqspi) != HAL_OK)
  {
    Error_Handler();
  }

}

static void MX_SDMMC1_SD_Init(void)
{

  hsd1.Instance = SDMMC1;
  hsd1.Init.ClockEdge = SDMMC_CLOCK_EDGE_RISING;
  hsd1.Init.ClockPowerSave = SDMMC_CLOCK_POWER_SAVE_DISABLE;
  hsd1.Init.BusWide = SDMMC_BUS_WIDE_4B;
  hsd1.Init.HardwareFlowControl = SDMMC_HARDWARE_FLOW_CONTROL_DISABLE;
  hsd1.Init.ClockDiv = 6;
  if (HAL_SD_Init(&hsd1) != HAL_OK)
  {
    Error_Handler();
  }

}

static void MX_SPI6_Init(void)
{

  /* SPI6 parameter configuration*/
  hspi6.Instance = SPI6;
  hspi6.Init.Mode = SPI_MODE_MASTER;
  hspi6.Init.Direction = SPI_DIRECTION_1LINE;
  hspi6.Init.DataSize = SPI_DATASIZE_8BIT;
  hspi6.Init.CLKPolarity = SPI_POLARITY_LOW;
  hspi6.Init.CLKPhase = SPI_PHASE_1EDGE;
  hspi6.Init.NSS = SPI_NSS_HARD_OUTPUT;
  hspi6.Init.BaudRatePrescaler = SPI_BAUDRATEPRESCALER_2;
  hspi6.Init.FirstBit = SPI_FIRSTBIT_MSB;
  hspi6.Init.TIMode = SPI_TIMODE_DISABLE;
  hspi6.Init.CRCCalculation = SPI_CRCCALCULATION_DISABLE;
  hspi6.Init.CRCPolynomial = 0x0;
  hspi6.Init.NSSPMode = SPI_NSS_PULSE_ENABLE;
  hspi6.Init.NSSPolarity = SPI_NSS_POLARITY_LOW;
  hspi6.Init.FifoThreshold = SPI_FIFO_THRESHOLD_01DATA;
  hspi6.Init.TxCRCInitializationPattern = SPI_CRC_INITIALIZATION_ALL_ZERO_PATTERN;
  hspi6.Init.RxCRCInitializationPattern = SPI_CRC_INITIALIZATION_ALL_ZERO_PATTERN;
  hspi6.Init.MasterSSIdleness = SPI_MASTER_SS_IDLENESS_00CYCLE;
  hspi6.Init.MasterInterDataIdleness = SPI_MASTER_INTERDATA_IDLENESS_00CYCLE;
  hspi6.Init.MasterReceiverAutoSusp = SPI_MASTER_RX_AUTOSUSP_DISABLE;
  hspi6.Init.MasterKeepIOState = SPI_MASTER_KEEP_IO_STATE_DISABLE;
  hspi6.Init.IOSwap = SPI_IO_SWAP_DISABLE;
  if (HAL_SPI_Init(&hspi6) != HAL_OK)
  {
    Error_Handler();
  }

}

static void MX_TIM1_Init(void)
{

  TIM_MasterConfigTypeDef sMasterConfig = {0};
  TIM_OC_InitTypeDef sConfigOC = {0};
  TIM_BreakDeadTimeConfigTypeDef sBreakDeadTimeConfig = {0};

  htim1.Instance = TIM1;
  htim1.Init.Prescaler = 239;
  htim1.Init.CounterMode = TIM_COUNTERMODE_UP;
  htim1.Init.Period = 999;
  htim1.Init.ClockDivision = TIM_CLOCKDIVISION_DIV1;
  htim1.Init.RepetitionCounter = 0;
  htim1.Init.AutoReloadPreload = TIM_AUTORELOAD_PRELOAD_DISABLE;
  if (HAL_TIM_PWM_Init(&htim1) != HAL_OK)
  {
    Error_Handler();
  }
  sMasterConfig.MasterOutputTrigger = TIM_TRGO_RESET;
  sMasterConfig.MasterOutputTrigger2 = TIM_TRGO2_RESET;
  sMasterConfig.MasterSlaveMode = TIM_MASTERSLAVEMODE_DISABLE;
  if (HAL_TIMEx_MasterConfigSynchronization(&htim1, &sMasterConfig) != HAL_OK)
  {
    Error_Handler();
  }
  sConfigOC.OCMode = TIM_OCMODE_PWM1;
  sConfigOC.Pulse = 0;
  sConfigOC.OCPolarity = TIM_OCPOLARITY_HIGH;
  sConfigOC.OCNPolarity = TIM_OCNPOLARITY_HIGH;
  sConfigOC.OCFastMode = TIM_OCFAST_DISABLE;
  sConfigOC.OCIdleState = TIM_OCIDLESTATE_RESET;
  sConfigOC.OCNIdleState = TIM_OCNIDLESTATE_RESET;
  if (HAL_TIM_PWM_ConfigChannel(&htim1, &sConfigOC, TIM_CHANNEL_1) != HAL_OK)
  {
    Error_Handler();
  }
  if (HAL_TIM_PWM_ConfigChannel(&htim1, &sConfigOC, TIM_CHANNEL_2) != HAL_OK)
  {
    Error_Handler();
  }
  if (HAL_TIM_PWM_ConfigChannel(&htim1, &sConfigOC, TIM_CHANNEL_3) != HAL_OK)
  {
    Error_Handler();
  }
  if (HAL_TIM_PWM_ConfigChannel(&htim1, &sConfigOC, TIM_CHANNEL_4) != HAL_OK)
  {
    Error_Handler();
  }
  sBreakDeadTimeConfig.OffStateRunMode = TIM_OSSR_DISABLE;
  sBreakDeadTimeConfig.OffStateIDLEMode = TIM_OSSI_DISABLE;
  sBreakDeadTimeConfig.LockLevel = TIM_LOCKLEVEL_OFF;
  sBreakDeadTimeConfig.DeadTime = 0;
  sBreakDeadTimeConfig.BreakState = TIM_BREAK_DISABLE;
  sBreakDeadTimeConfig.BreakPolarity = TIM_BREAKPOLARITY_HIGH;
  sBreakDeadTimeConfig.BreakFilter = 0;
  sBreakDeadTimeConfig.Break2State = TIM_BREAK2_DISABLE;
  sBreakDeadTimeConfig.Break2Polarity = TIM_BREAK2POLARITY_HIGH;
  sBreakDeadTimeConfig.Break2Filter = 0;
  sBreakDeadTimeConfig.AutomaticOutput = TIM_AUTOMATICOUTPUT_DISABLE;
  if (HAL_TIMEx_ConfigBreakDeadTime(&htim1, &sBreakDeadTimeConfig) != HAL_OK)
  {
    Error_Handler();
  }
  HAL_TIM_MspPostInit(&htim1);

}

static void MX_TIM2_Init(void)
{

  TIM_Encoder_InitTypeDef sConfig = {0};
  TIM_MasterConfigTypeDef sMasterConfig = {0};

  htim2.Instance = TIM2;
  htim2.Init.Prescaler = 0;
  htim2.Init.CounterMode = TIM_COUNTERMODE_UP;
  htim2.Init.Period = 4294967295;
  htim2.Init.ClockDivision = TIM_CLOCKDIVISION_DIV1;
  htim2.Init.AutoReloadPreload = TIM_AUTORELOAD_PRELOAD_DISABLE;
  sConfig.EncoderMode = TIM_ENCODERMODE_TI1;
  sConfig.IC1Polarity = TIM_ICPOLARITY_RISING;
  sConfig.IC1Selection = TIM_ICSELECTION_DIRECTTI;
  sConfig.IC1Prescaler = TIM_ICPSC_DIV1;
  sConfig.IC1Filter = 0;
  sConfig.IC2Polarity = TIM_ICPOLARITY_RISING;
  sConfig.IC2Selection = TIM_ICSELECTION_DIRECTTI;
  sConfig.IC2Prescaler = TIM_ICPSC_DIV1;
  sConfig.IC2Filter = 0;
  if (HAL_TIM_Encoder_Init(&htim2, &sConfig) != HAL_OK)
  {
    Error_Handler();
  }
  sMasterConfig.MasterOutputTrigger = TIM_TRGO_RESET;
  sMasterConfig.MasterSlaveMode = TIM_MASTERSLAVEMODE_DISABLE;
  if (HAL_TIMEx_MasterConfigSynchronization(&htim2, &sMasterConfig) != HAL_OK)
  {
    Error_Handler();
  }

}

static void MX_TIM3_Init(void)
{

  TIM_Encoder_InitTypeDef sConfig = {0};
  TIM_MasterConfigTypeDef sMasterConfig = {0};

  htim3.Instance = TIM3;
  htim3.Init.Prescaler = 0;
  htim3.Init.CounterMode = TIM_COUNTERMODE_UP;
  htim3.Init.Period = 65535;
  htim3.Init.ClockDivision = TIM_CLOCKDIVISION_DIV1;
  htim3.Init.AutoReloadPreload = TIM_AUTORELOAD_PRELOAD_DISABLE;
  sConfig.EncoderMode = TIM_ENCODERMODE_TI1;
  sConfig.IC1Polarity = TIM_ICPOLARITY_RISING;
  sConfig.IC1Selection = TIM_ICSELECTION_DIRECTTI;
  sConfig.IC1Prescaler = TIM_ICPSC_DIV1;
  sConfig.IC1Filter = 0;
  sConfig.IC2Polarity = TIM_ICPOLARITY_RISING;
  sConfig.IC2Selection = TIM_ICSELECTION_DIRECTTI;
  sConfig.IC2Prescaler = TIM_ICPSC_DIV1;
  sConfig.IC2Filter = 0;
  if (HAL_TIM_Encoder_Init(&htim3, &sConfig) != HAL_OK)
  {
    Error_Handler();
  }
  sMasterConfig.MasterOutputTrigger = TIM_TRGO_RESET;
  sMasterConfig.MasterSlaveMode = TIM_MASTERSLAVEMODE_DISABLE;
  if (HAL_TIMEx_MasterConfigSynchronization(&htim3, &sMasterConfig) != HAL_OK)
  {
    Error_Handler();
  }

}

static void MX_TIM4_Init(void)
{

  TIM_Encoder_InitTypeDef sConfig = {0};
  TIM_MasterConfigTypeDef sMasterConfig = {0};

  htim4.Instance = TIM4;
  htim4.Init.Prescaler = 0;
  htim4.Init.CounterMode = TIM_COUNTERMODE_UP;
  htim4.Init.Period = 65535;
  htim4.Init.ClockDivision = TIM_CLOCKDIVISION_DIV1;
  htim4.Init.AutoReloadPreload = TIM_AUTORELOAD_PRELOAD_DISABLE;
  sConfig.EncoderMode = TIM_ENCODERMODE_TI1;
  sConfig.IC1Polarity = TIM_ICPOLARITY_RISING;
  sConfig.IC1Selection = TIM_ICSELECTION_DIRECTTI;
  sConfig.IC1Prescaler = TIM_ICPSC_DIV1;
  sConfig.IC1Filter = 0;
  sConfig.IC2Polarity = TIM_ICPOLARITY_RISING;
  sConfig.IC2Selection = TIM_ICSELECTION_DIRECTTI;
  sConfig.IC2Prescaler = TIM_ICPSC_DIV1;
  sConfig.IC2Filter = 0;
  if (HAL_TIM_Encoder_Init(&htim4, &sConfig) != HAL_OK)
  {
    Error_Handler();
  }
  sMasterConfig.MasterOutputTrigger = TIM_TRGO_RESET;
  sMasterConfig.MasterSlaveMode = TIM_MASTERSLAVEMODE_DISABLE;
  if (HAL_TIMEx_MasterConfigSynchronization(&htim4, &sMasterConfig) != HAL_OK)
  {
    Error_Handler();
  }

}

static void MX_TIM5_Init(void)
{

  TIM_Encoder_InitTypeDef sConfig = {0};
  TIM_MasterConfigTypeDef sMasterConfig = {0};

  htim5.Instance = TIM5;
  htim5.Init.Prescaler = 0;
  htim5.Init.CounterMode = TIM_COUNTERMODE_UP;
  htim5.Init.Period = 4294967295;
  htim5.Init.ClockDivision = TIM_CLOCKDIVISION_DIV1;
  htim5.Init.AutoReloadPreload = TIM_AUTORELOAD_PRELOAD_DISABLE;
  sConfig.EncoderMode = TIM_ENCODERMODE_TI1;
  sConfig.IC1Polarity = TIM_ICPOLARITY_RISING;
  sConfig.IC1Selection = TIM_ICSELECTION_DIRECTTI;
  sConfig.IC1Prescaler = TIM_ICPSC_DIV1;
  sConfig.IC1Filter = 0;
  sConfig.IC2Polarity = TIM_ICPOLARITY_RISING;
  sConfig.IC2Selection = TIM_ICSELECTION_DIRECTTI;
  sConfig.IC2Prescaler = TIM_ICPSC_DIV1;
  sConfig.IC2Filter = 0;
  if (HAL_TIM_Encoder_Init(&htim5, &sConfig) != HAL_OK)
  {
    Error_Handler();
  }
  sMasterConfig.MasterOutputTrigger = TIM_TRGO_RESET;
  sMasterConfig.MasterSlaveMode = TIM_MASTERSLAVEMODE_DISABLE;
  if (HAL_TIMEx_MasterConfigSynchronization(&htim5, &sMasterConfig) != HAL_OK)
  {
    Error_Handler();
  }

}

static void MX_TIM6_Init(void)
{

  TIM_MasterConfigTypeDef sMasterConfig = {0};

  htim6.Instance = TIM6;
  htim6.Init.Prescaler = 239;
  htim6.Init.CounterMode = TIM_COUNTERMODE_UP;
  htim6.Init.Period = 999;
  htim6.Init.AutoReloadPreload = TIM_AUTORELOAD_PRELOAD_DISABLE;
  if (HAL_TIM_Base_Init(&htim6) != HAL_OK)
  {
    Error_Handler();
  }
  sMasterConfig.MasterOutputTrigger = TIM_TRGO_RESET;
  sMasterConfig.MasterSlaveMode = TIM_MASTERSLAVEMODE_DISABLE;
  if (HAL_TIMEx_MasterConfigSynchronization(&htim6, &sMasterConfig) != HAL_OK)
  {
    Error_Handler();
  }

}

static void MX_TIM7_Init(void)
{

  TIM_MasterConfigTypeDef sMasterConfig = {0};

  htim7.Instance = TIM7;
  htim7.Init.Prescaler = 24000-1;
  htim7.Init.CounterMode = TIM_COUNTERMODE_UP;
  htim7.Init.Period = 332;
  htim7.Init.AutoReloadPreload = TIM_AUTORELOAD_PRELOAD_DISABLE;
  if (HAL_TIM_Base_Init(&htim7) != HAL_OK)
  {
    Error_Handler();
  }
  sMasterConfig.MasterOutputTrigger = TIM_TRGO_RESET;
  sMasterConfig.MasterSlaveMode = TIM_MASTERSLAVEMODE_DISABLE;
  if (HAL_TIMEx_MasterConfigSynchronization(&htim7, &sMasterConfig) != HAL_OK)
  {
    Error_Handler();
  }

}

static void MX_TIM13_Init(void)
{

  htim13.Instance = TIM13;
  htim13.Init.Prescaler = 2399;
  htim13.Init.CounterMode = TIM_COUNTERMODE_UP;
  htim13.Init.Period = 999;
  htim13.Init.ClockDivision = TIM_CLOCKDIVISION_DIV1;
  htim13.Init.AutoReloadPreload = TIM_AUTORELOAD_PRELOAD_DISABLE;
  if (HAL_TIM_Base_Init(&htim13) != HAL_OK)
  {
    Error_Handler();
  }

}

static void MX_TIM15_Init(void)
{

  TIM_MasterConfigTypeDef sMasterConfig = {0};
  TIM_OC_InitTypeDef sConfigOC = {0};
  TIM_BreakDeadTimeConfigTypeDef sBreakDeadTimeConfig = {0};

  htim15.Instance = TIM15;
  htim15.Init.Prescaler = 0;
  htim15.Init.CounterMode = TIM_COUNTERMODE_UP;
  htim15.Init.Period = 299;
  htim15.Init.ClockDivision = TIM_CLOCKDIVISION_DIV1;
  htim15.Init.RepetitionCounter = 0;
  htim15.Init.AutoReloadPreload = TIM_AUTORELOAD_PRELOAD_DISABLE;
  if (HAL_TIM_PWM_Init(&htim15) != HAL_OK)
  {
    Error_Handler();
  }
  sMasterConfig.MasterOutputTrigger = TIM_TRGO_RESET;
  sMasterConfig.MasterSlaveMode = TIM_MASTERSLAVEMODE_DISABLE;
  if (HAL_TIMEx_MasterConfigSynchronization(&htim15, &sMasterConfig) != HAL_OK)
  {
    Error_Handler();
  }
  sConfigOC.OCMode = TIM_OCMODE_PWM1;
  sConfigOC.Pulse = 0;
  sConfigOC.OCPolarity = TIM_OCPOLARITY_HIGH;
  sConfigOC.OCNPolarity = TIM_OCNPOLARITY_HIGH;
  sConfigOC.OCFastMode = TIM_OCFAST_DISABLE;
  sConfigOC.OCIdleState = TIM_OCIDLESTATE_RESET;
  sConfigOC.OCNIdleState = TIM_OCNIDLESTATE_RESET;
  if (HAL_TIM_PWM_ConfigChannel(&htim15, &sConfigOC, TIM_CHANNEL_2) != HAL_OK)
  {
    Error_Handler();
  }
  sBreakDeadTimeConfig.OffStateRunMode = TIM_OSSR_DISABLE;
  sBreakDeadTimeConfig.OffStateIDLEMode = TIM_OSSI_DISABLE;
  sBreakDeadTimeConfig.LockLevel = TIM_LOCKLEVEL_OFF;
  sBreakDeadTimeConfig.DeadTime = 0;
  sBreakDeadTimeConfig.BreakState = TIM_BREAK_DISABLE;
  sBreakDeadTimeConfig.BreakPolarity = TIM_BREAKPOLARITY_HIGH;
  sBreakDeadTimeConfig.BreakFilter = 0;
  sBreakDeadTimeConfig.AutomaticOutput = TIM_AUTOMATICOUTPUT_DISABLE;
  if (HAL_TIMEx_ConfigBreakDeadTime(&htim15, &sBreakDeadTimeConfig) != HAL_OK)
  {
    Error_Handler();
  }
  HAL_TIM_MspPostInit(&htim15);

}

static void MX_TIM16_Init(void)
{

  htim16.Instance = TIM16;
  htim16.Init.Prescaler = 24000-1;
  htim16.Init.CounterMode = TIM_COUNTERMODE_UP;
  htim16.Init.Period = 10000-1;
  htim16.Init.ClockDivision = TIM_CLOCKDIVISION_DIV1;
  htim16.Init.RepetitionCounter = 0;
  htim16.Init.AutoReloadPreload = TIM_AUTORELOAD_PRELOAD_DISABLE;
  if (HAL_TIM_Base_Init(&htim16) != HAL_OK)
  {
    Error_Handler();
  }

}

static void MX_UART4_Init(void)
{

  huart4.Instance = UART4;
  huart4.Init.BaudRate = 115200;
  huart4.Init.WordLength = UART_WORDLENGTH_8B;
  huart4.Init.StopBits = UART_STOPBITS_1;
  huart4.Init.Parity = UART_PARITY_NONE;
  huart4.Init.Mode = UART_MODE_TX_RX;
  huart4.Init.HwFlowCtl = UART_HWCONTROL_NONE;
  huart4.Init.OverSampling = UART_OVERSAMPLING_16;
  huart4.Init.OneBitSampling = UART_ONE_BIT_SAMPLE_DISABLE;
  huart4.Init.ClockPrescaler = UART_PRESCALER_DIV1;
  huart4.AdvancedInit.AdvFeatureInit = UART_ADVFEATURE_NO_INIT;
  if (HAL_UART_Init(&huart4) != HAL_OK)
  {
    Error_Handler();
  }
  if (HAL_UARTEx_SetTxFifoThreshold(&huart4, UART_TXFIFO_THRESHOLD_1_8) != HAL_OK)
  {
    Error_Handler();
  }
  if (HAL_UARTEx_SetRxFifoThreshold(&huart4, UART_RXFIFO_THRESHOLD_1_8) != HAL_OK)
  {
    Error_Handler();
  }
  if (HAL_UARTEx_DisableFifoMode(&huart4) != HAL_OK)
  {
    Error_Handler();
  }

}

static void MX_UART5_Init(void)
{

  huart5.Instance = UART5;
  huart5.Init.BaudRate = 2500000;
  huart5.Init.WordLength = UART_WORDLENGTH_8B;
  huart5.Init.StopBits = UART_STOPBITS_1;
  huart5.Init.Parity = UART_PARITY_NONE;
  huart5.Init.Mode = UART_MODE_TX_RX;
  huart5.Init.HwFlowCtl = UART_HWCONTROL_NONE;
  huart5.Init.OverSampling = UART_OVERSAMPLING_16;
  huart5.Init.OneBitSampling = UART_ONE_BIT_SAMPLE_DISABLE;
  huart5.Init.ClockPrescaler = UART_PRESCALER_DIV1;
  huart5.AdvancedInit.AdvFeatureInit = UART_ADVFEATURE_NO_INIT;
  if (HAL_UART_Init(&huart5) != HAL_OK)
  {
    Error_Handler();
  }
  if (HAL_UARTEx_SetTxFifoThreshold(&huart5, UART_TXFIFO_THRESHOLD_1_8) != HAL_OK)
  {
    Error_Handler();
  }
  if (HAL_UARTEx_SetRxFifoThreshold(&huart5, UART_RXFIFO_THRESHOLD_1_8) != HAL_OK)
  {
    Error_Handler();
  }
  if (HAL_UARTEx_DisableFifoMode(&huart5) != HAL_OK)
  {
    Error_Handler();
  }

}

static void MX_USART1_UART_Init(void)
{

  huart1.Instance = USART1;
  huart1.Init.BaudRate = 115200;
  huart1.Init.WordLength = UART_WORDLENGTH_8B;
  huart1.Init.StopBits = UART_STOPBITS_1;
  huart1.Init.Parity = UART_PARITY_NONE;
  huart1.Init.Mode = UART_MODE_TX_RX;
  huart1.Init.HwFlowCtl = UART_HWCONTROL_NONE;
  huart1.Init.OverSampling = UART_OVERSAMPLING_16;
  huart1.Init.OneBitSampling = UART_ONE_BIT_SAMPLE_DISABLE;
  huart1.Init.ClockPrescaler = UART_PRESCALER_DIV1;
  huart1.AdvancedInit.AdvFeatureInit = UART_ADVFEATURE_NO_INIT;
  if (HAL_UART_Init(&huart1) != HAL_OK)
  {
    Error_Handler();
  }
  if (HAL_UARTEx_SetTxFifoThreshold(&huart1, UART_TXFIFO_THRESHOLD_1_8) != HAL_OK)
  {
    Error_Handler();
  }
  if (HAL_UARTEx_SetRxFifoThreshold(&huart1, UART_RXFIFO_THRESHOLD_1_8) != HAL_OK)
  {
    Error_Handler();
  }
  if (HAL_UARTEx_DisableFifoMode(&huart1) != HAL_OK)
  {
    Error_Handler();
  }

}

static void MX_BDMA_Init(void)
{

  /* DMA controller clock enable */
  __HAL_RCC_BDMA_CLK_ENABLE();

  /* DMA interrupt init */
  /* BDMA_Channel0_IRQn interrupt configuration */
  HAL_NVIC_SetPriority(BDMA_Channel0_IRQn, 7, 0);
  HAL_NVIC_EnableIRQ(BDMA_Channel0_IRQn);

}

static void MX_DMA_Init(void)
{

  /* DMA controller clock enable */
  __HAL_RCC_DMA1_CLK_ENABLE();

  /* DMA interrupt init */
  /* DMA1_Stream0_IRQn interrupt configuration */
  HAL_NVIC_SetPriority(DMA1_Stream0_IRQn, 7, 0);
  HAL_NVIC_EnableIRQ(DMA1_Stream0_IRQn);
  /* DMA1_Stream1_IRQn interrupt configuration */
  HAL_NVIC_SetPriority(DMA1_Stream1_IRQn, 6, 0);
  HAL_NVIC_EnableIRQ(DMA1_Stream1_IRQn);
  /* DMA1_Stream2_IRQn interrupt configuration */
  HAL_NVIC_SetPriority(DMA1_Stream2_IRQn, 7, 0);
  HAL_NVIC_EnableIRQ(DMA1_Stream2_IRQn);

}

/**
  * Enable MDMA controller clock
  */
static void MX_MDMA_Init(void)
{

  /* MDMA controller clock enable */
  __HAL_RCC_MDMA_CLK_ENABLE();
  /* Local variables */

  /* MDMA interrupt initialization */
  /* MDMA_IRQn interrupt configuration */
  HAL_NVIC_SetPriority(MDMA_IRQn, 9, 0);
  HAL_NVIC_EnableIRQ(MDMA_IRQn);

}

static void MX_GPIO_Init(void)
{
  GPIO_InitTypeDef GPIO_InitStruct = {0};

  /* GPIO Ports Clock Enable */
  __HAL_RCC_GPIOE_CLK_ENABLE();
  __HAL_RCC_GPIOC_CLK_ENABLE();
  __HAL_RCC_GPIOF_CLK_ENABLE();
  __HAL_RCC_GPIOH_CLK_ENABLE();
  __HAL_RCC_GPIOA_CLK_ENABLE();
  __HAL_RCC_GPIOB_CLK_ENABLE();
  __HAL_RCC_GPIOD_CLK_ENABLE();
  __HAL_RCC_GPIOG_CLK_ENABLE();

  /*Configure GPIO pin Output Level */
  HAL_GPIO_WritePin(GPIOC, LED1_Pin|LED2_Pin, GPIO_PIN_SET);

  /*Configure GPIO pin Output Level */
  HAL_GPIO_WritePin(BUZZER_GPIO_Port, BUZZER_Pin, GPIO_PIN_RESET);

  /*Configure GPIO pin Output Level */
  HAL_GPIO_WritePin(OV_PWDN_GPIO_Port, OV_PWDN_Pin, GPIO_PIN_SET);

  /*Configure GPIO pin Output Level */
  HAL_GPIO_WritePin(GPIOG, M1_PH_Pin|M2_PH_Pin|M3_PH_Pin|M4_PH_Pin
                          |LCD_BL_Pin|LCD_DC_Pin, GPIO_PIN_RESET);

  /*Configure GPIO pin Output Level */
  HAL_GPIO_WritePin(LED0_GPIO_Port, LED0_Pin, GPIO_PIN_SET);

  /*Configure GPIO pins : Key_Up_Pin Key_Down_Pin Key_Left_Pin Key_Right_Pin
                           Key_OK_Pin Key1_Pin */
  GPIO_InitStruct.Pin = Key_Up_Pin|Key_Down_Pin|Key_Left_Pin|Key_Right_Pin
                          |Key_OK_Pin|Key1_Pin;
  GPIO_InitStruct.Mode = GPIO_MODE_INPUT;
  GPIO_InitStruct.Pull = GPIO_PULLUP;
  HAL_GPIO_Init(GPIOF, &GPIO_InitStruct);

  /*Configure GPIO pins : LED1_Pin LED2_Pin */
  GPIO_InitStruct.Pin = LED1_Pin|LED2_Pin;
  GPIO_InitStruct.Mode = GPIO_MODE_OUTPUT_PP;
  GPIO_InitStruct.Pull = GPIO_PULLUP;
  GPIO_InitStruct.Speed = GPIO_SPEED_FREQ_LOW;
  HAL_GPIO_Init(GPIOC, &GPIO_InitStruct);

  /*Configure GPIO pin : BUZZER_Pin */
  GPIO_InitStruct.Pin = BUZZER_Pin;
  GPIO_InitStruct.Mode = GPIO_MODE_OUTPUT_PP;
  GPIO_InitStruct.Pull = GPIO_NOPULL;
  GPIO_InitStruct.Speed = GPIO_SPEED_FREQ_LOW;
  HAL_GPIO_Init(BUZZER_GPIO_Port, &GPIO_InitStruct);

  /*Configure GPIO pins : SD_Pin Key2_Pin Key3_Pin */
  GPIO_InitStruct.Pin = SD_Pin|Key2_Pin|Key3_Pin;
  GPIO_InitStruct.Mode = GPIO_MODE_INPUT;
  GPIO_InitStruct.Pull = GPIO_PULLUP;
  HAL_GPIO_Init(GPIOB, &GPIO_InitStruct);

  /*Configure GPIO pin : OV_PWDN_Pin */
  GPIO_InitStruct.Pin = OV_PWDN_Pin;
  GPIO_InitStruct.Mode = GPIO_MODE_OUTPUT_PP;
  GPIO_InitStruct.Pull = GPIO_NOPULL;
  GPIO_InitStruct.Speed = GPIO_SPEED_FREQ_LOW;
  HAL_GPIO_Init(OV_PWDN_GPIO_Port, &GPIO_InitStruct);

  /*Configure GPIO pins : M1_PH_Pin M2_PH_Pin M3_PH_Pin M4_PH_Pin */
  GPIO_InitStruct.Pin = M1_PH_Pin|M2_PH_Pin|M3_PH_Pin|M4_PH_Pin;
  GPIO_InitStruct.Mode = GPIO_MODE_OUTPUT_PP;
  GPIO_InitStruct.Pull = GPIO_PULLDOWN;
  GPIO_InitStruct.Speed = GPIO_SPEED_FREQ_HIGH;
  HAL_GPIO_Init(GPIOG, &GPIO_InitStruct);

  /*Configure GPIO pin : LED0_Pin */
  GPIO_InitStruct.Pin = LED0_Pin;
  GPIO_InitStruct.Mode = GPIO_MODE_OUTPUT_PP;
  GPIO_InitStruct.Pull = GPIO_PULLUP;
  GPIO_InitStruct.Speed = GPIO_SPEED_FREQ_LOW;
  HAL_GPIO_Init(LED0_GPIO_Port, &GPIO_InitStruct);

  /*Configure GPIO pins : LCD_BL_Pin LCD_DC_Pin */
  GPIO_InitStruct.Pin = LCD_BL_Pin|LCD_DC_Pin;
  GPIO_InitStruct.Mode = GPIO_MODE_OUTPUT_PP;
  GPIO_InitStruct.Pull = GPIO_NOPULL;
  GPIO_InitStruct.Speed = GPIO_SPEED_FREQ_LOW;
  HAL_GPIO_Init(GPIOG, &GPIO_InitStruct);

  /*AnalogSwitch Config */
  HAL_SYSCFG_AnalogSwitchConfig(SYSCFG_SWITCH_PC2, SYSCFG_SWITCH_PC2_CLOSE);

  /*AnalogSwitch Config */
  HAL_SYSCFG_AnalogSwitchConfig(SYSCFG_SWITCH_PC3, SYSCFG_SWITCH_PC3_CLOSE);

}

 /* MPU Configuration */

void MPU_Config(void)
{
  MPU_Region_InitTypeDef MPU_InitStruct = {0};

  /* Disables the MPU */
  HAL_MPU_Disable();

  /** Initializes and configures the Region and the memory to be protected
  */
  MPU_InitStruct.Enable = MPU_REGION_ENABLE;
  MPU_InitStruct.Number = MPU_REGION_NUMBER0;
  MPU_InitStruct.BaseAddress = 0x0;
  MPU_InitStruct.Size = MPU_REGION_SIZE_4GB;
  MPU_InitStruct.SubRegionDisable = 0x87;
  MPU_InitStruct.TypeExtField = MPU_TEX_LEVEL0;
  MPU_InitStruct.AccessPermission = MPU_REGION_NO_ACCESS;
  MPU_InitStruct.DisableExec = MPU_INSTRUCTION_ACCESS_DISABLE;
  MPU_InitStruct.IsShareable = MPU_ACCESS_SHAREABLE;
  MPU_InitStruct.IsCacheable = MPU_ACCESS_NOT_CACHEABLE;
  MPU_InitStruct.IsBufferable = MPU_ACCESS_NOT_BUFFERABLE;

  HAL_MPU_ConfigRegion(&MPU_InitStruct);
  /* Enables the MPU */
  HAL_MPU_Enable(MPU_PRIVILEGED_DEFAULT);

}

void Error_Handler(void)
{
  /* USER CODE BEGIN Error_Handler_Debug */
  RuntimeMonitor_CaptureFaultAndReset(RUNTIME_FAULT_ERROR_HANDLER, NULL, 0U);
  /* USER CODE END Error_Handler_Debug */
}
